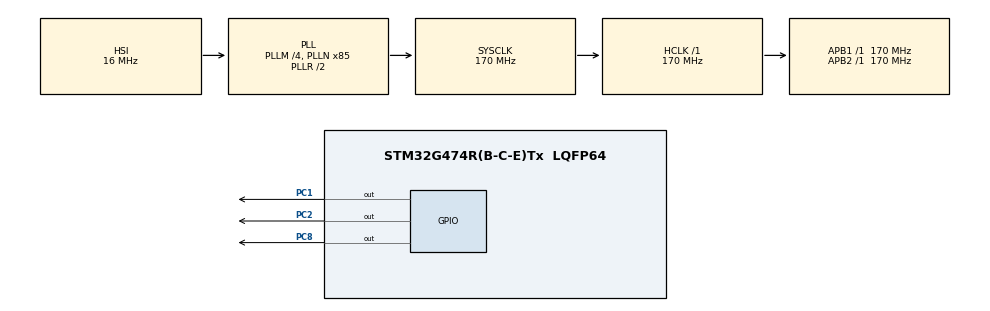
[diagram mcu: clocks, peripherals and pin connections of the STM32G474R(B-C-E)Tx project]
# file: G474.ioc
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Mcu.Family=STM32G4
Mcu.Name=STM32G474R(B-C-E)Tx
Mcu.Package=LQFP64
NVIC.PriorityGroup=NVIC_PRIORITYGROUP_4
PA13.Mode=Serial_Wire
PA13.Signal=SYS_JTMS-SWDIO
PA14.Mode=Serial_Wire
PA14.Signal=SYS_JTCK-SWCLK
PC1.Signal=GPIO_Output
PC2.Signal=GPIO_Output
PC8.Signal=GPIO_Output
ProjectManager.HeapSize=0x200
ProjectManager.StackSize=0x400
ProjectManager.TargetToolchain=MDK-ARM V5.27
RCC.ADC12Freq_Value=170000000
RCC.ADC345Freq_Value=170000000
RCC.AHBFreq_Value=170000000
RCC.APB1Freq_Value=170000000
RCC.APB1TimFreq_Value=170000000
RCC.APB2Freq_Value=170000000
RCC.APB2TimFreq_Value=170000000
RCC.CortexFreq_Value=170000000
RCC.EXTERNAL_CLOCK_VALUE=12288000
RCC.HCLKFreq_Value=170000000
RCC.HSE_VALUE=8000000
RCC.HSI48_VALUE=48000000
RCC.HSI_VALUE=16000000
RCC.LSE_VALUE=32768
RCC.PLLM=RCC_PLLM_DIV4
RCC.PLLN=85
RCC.SYSCLKFreq_VALUE=170000000
RCC.SYSCLKSource=RCC_SYSCLKSOURCE_PLLCLK
RCC.USBFreq_Value=170000000
RCC.VCOOutputFreq_Value=340000000
VP_SYS_VS_DBSignals.Mode=DisableDeadBatterySignals
board=custom

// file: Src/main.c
/* USER CODE BEGIN Header */
/**
  ******************************************************************************
  * @file           : main.c
  * @brief          : Main program body
  ******************************************************************************
  * @attention
  *
  * <h2><center>&copy; Copyright (c) 2020 STMicroelectronics.
  * All rights reserved.</center></h2>
  *
  * This software component is licensed by ST under BSD 3-Clause license,
  * the "License"; You may not use this file except in compliance with the
  * License. You may obtain a copy of the License at:
  *                        opensource.org/licenses/BSD-3-Clause
  *
  ******************************************************************************
  */
/* USER CODE END Header */

#include "main.h"
#include "gpio.h"

void SystemClock_Config(void);
/* USER CODE BEGIN PFP */
	unsigned char EEDATA;
extern void EE_IIC_Init(void);
extern uint8_t EE_EE_IIC_SendByteToSlave(uint8_t I2C_Addr,uint8_t reg,uint8_t data);
extern uint8_t EE_IIC_ReadByteFromSlave(uint8_t I2C_Addr,uint8_t reg,uint8_t *buf);
/* USER CODE END PFP */

int main(void)
{

  /* MCU Configuration--------------------------------------------------------*/

  /* Reset of all peripherals, Initializes the Flash interface and the Systick. */

  /* USER CODE BEGIN Init */
  int i=0;
  int b=0;

  /* USER CODE END Init */

  /* Configure the system clock */
  SystemClock_Config();

  /* Initialize all configured peripherals */
  MX_GPIO_Init();
  /* USER CODE BEGIN 2 */
EE_IIC_Init();
	EE_EE_IIC_SendByteToSlave(0xA0,0x00,0x33);
	HAL_Delay(10);
	EE_IIC_ReadByteFromSlave(0xA0,0x00,&EEDATA);
  /* USER CODE END 2 */

  /* Infinite loop */
  while (1)
  {

    /* USER CODE BEGIN 3 */
		if(EEDATA==0x33)
		{
		HAL_Delay(100);
		HAL_GPIO_TogglePin(GPIOC, GPIO_PIN_8);
		}
  }
  /* USER CODE END 3 */
}

void SystemClock_Config(void)
{
  RCC_OscInitTypeDef RCC_OscInitStruct = {0};
  RCC_ClkInitTypeDef RCC_ClkInitStruct = {0};

  /** Configure the main internal regulator output voltage
  */
  HAL_PWREx_ControlVoltageScaling(PWR_REGULATOR_VOLTAGE_SCALE1_BOOST);
  /** Initializes the CPU, AHB and APB busses clocks
  */
  RCC_OscInitStruct.OscillatorType = RCC_OSCILLATORTYPE_HSI;
  RCC_OscInitStruct.HSIState = RCC_HSI_ON;
  RCC_OscInitStruct.HSICalibrationValue = RCC_HSICALIBRATION_DEFAULT;
  RCC_OscInitStruct.PLL.PLLState = RCC_PLL_ON;
  RCC_OscInitStruct.PLL.PLLSource = RCC_PLLSOURCE_HSI;
  RCC_OscInitStruct.PLL.PLLM = RCC_PLLM_DIV4;
  RCC_OscInitStruct.PLL.PLLN = 85;
  RCC_OscInitStruct.PLL.PLLP = RCC_PLLP_DIV2;
  RCC_OscInitStruct.PLL.PLLQ = RCC_PLLQ_DIV2;
  RCC_OscInitStruct.PLL.PLLR = RCC_PLLR_DIV2;
  if (HAL_RCC_OscConfig(&RCC_OscInitStruct) != HAL_OK)
  {
    Error_Handler();
  }
  /** Initializes the CPU, AHB and APB busses clocks
  */
  RCC_ClkInitStruct.ClockType = RCC_CLOCKTYPE_HCLK|RCC_CLOCKTYPE_SYSCLK
                              |RCC_CLOCKTYPE_PCLK1|RCC_CLOCKTYPE_PCLK2;
  RCC_ClkInitStruct.SYSCLKSource = RCC_SYSCLKSOURCE_PLLCLK;
  RCC_ClkInitStruct.AHBCLKDivider = RCC_SYSCLK_DIV1;
  RCC_ClkInitStruct.APB1CLKDivider = RCC_HCLK_DIV1;
  RCC_ClkInitStruct.APB2CLKDivider = RCC_HCLK_DIV1;

  if (HAL_RCC_ClockConfig(&RCC_ClkInitStruct, FLASH_LATENCY_8) != HAL_OK)
  {
    Error_Handler();
  }
}

void Error_Handler(void)
{
}

/************************ (C) COPYRIGHT STMicroelectronics *****END OF FILE****/
